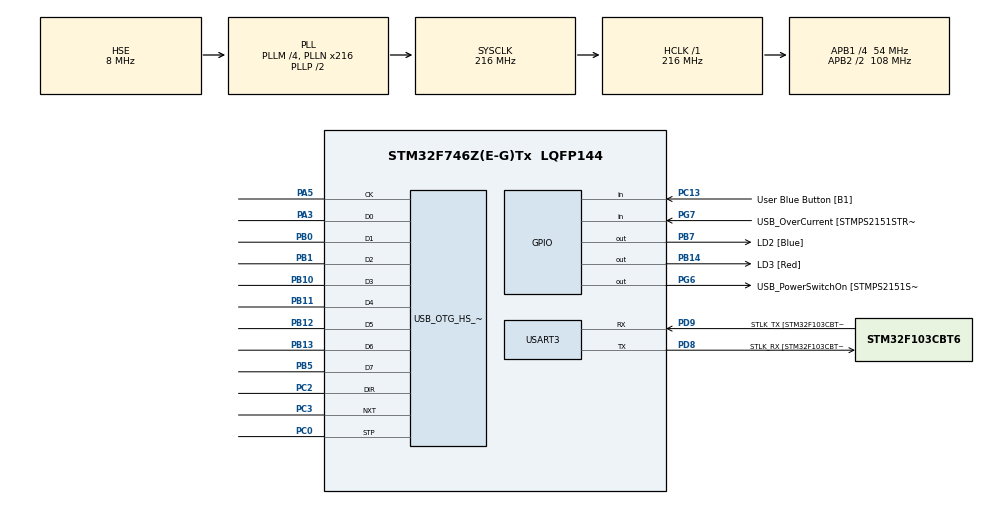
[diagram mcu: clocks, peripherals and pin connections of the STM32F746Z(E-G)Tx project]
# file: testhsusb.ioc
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Mcu.Family=STM32F7
Mcu.Name=STM32F746Z(E-G)Tx
Mcu.Package=LQFP144
NVIC.OTG_HS_IRQn=true\:0\:0\:false\:false\:true
NVIC.PriorityGroup=NVIC_PRIORITYGROUP_4
NVIC.TIM7_IRQn=true\:0\:0\:false\:false\:true
NVIC.TimeBase=TIM7_IRQn
NVIC.TimeBaseIP=TIM7
PA10.GPIO_Label=USB_ID
PA10.Signal=USB_OTG_FS_ID
PA11.GPIO_Label=USB_DM
PA11.Signal=USB_OTG_FS_DM
PA12.GPIO_Label=USB_DP
PA12.Signal=USB_OTG_FS_DP
PA13.GPIO_Label=TMS
PA13.Mode=Serial_Wire
PA13.Signal=SYS_JTMS-SWDIO
PA14.GPIO_Label=TCK
PA14.Mode=Serial_Wire
PA14.Signal=SYS_JTCK-SWCLK
PA3.Mode=Device_HS
PA3.Signal=USB_OTG_HS_ULPI_D0
PA5.Mode=Device_HS
PA5.Signal=USB_OTG_HS_ULPI_CK
PA8.GPIO_Label=USB_SOF [TP1]
PA8.Signal=USB_OTG_FS_SOF
PA9.GPIO_Label=USB_VBUS
PA9.Signal=USB_OTG_FS_VBUS
PB0.Mode=Device_HS
PB0.Signal=USB_OTG_HS_ULPI_D1
PB1.Mode=Device_HS
PB1.Signal=USB_OTG_HS_ULPI_D2
PB10.Mode=Device_HS
PB10.Signal=USB_OTG_HS_ULPI_D3
PB11.Mode=Device_HS
PB11.Signal=USB_OTG_HS_ULPI_D4
PB12.Mode=Device_HS
PB12.Signal=USB_OTG_HS_ULPI_D5
PB13.Mode=Device_HS
PB13.Signal=USB_OTG_HS_ULPI_D6
PB14.GPIO_Label=LD3 [Red]
PB14.Signal=GPIO_Output
PB5.Mode=Device_HS
PB5.Signal=USB_OTG_HS_ULPI_D7
PB7.GPIO_Label=LD2 [Blue]
PB7.Signal=GPIO_Output
PC0.Mode=Device_HS
PC0.Signal=USB_OTG_HS_ULPI_STP
PC13.GPIO_Label=User Blue Button [B1]
PC13.Signal=GPIO_Input
PC14/OSC32_IN.Mode=LSE-External-Oscillator
PC14/OSC32_IN.Signal=RCC_OSC32_IN
PC15/OSC32_OUT.Mode=LSE-External-Oscillator
PC15/OSC32_OUT.Signal=RCC_OSC32_OUT
PC2.Mode=Device_HS
PC2.Signal=USB_OTG_HS_ULPI_DIR
PC3.Mode=Device_HS
PC3.Signal=USB_OTG_HS_ULPI_NXT
PD8.GPIO_Label=STLK_RX [STM32F103CBT6_PA3]
PD8.Mode=Asynchronous
PD8.Signal=USART3_TX
PD9.GPIO_Label=STLK_TX [STM32F103CBT6_PA2]
PD9.Mode=Asynchronous
PD9.Signal=USART3_RX
PG6.GPIO_Label=USB_PowerSwitchOn [STMPS2151STR_EN]
PG6.Signal=GPIO_Output
PG7.GPIO_Label=USB_OverCurrent [STMPS2151STR_FAULT]
PG7.Signal=GPIO_Input
PH0/OSC_IN.GPIO_Label=MCO [STM32F103CBT6_PA8]
PH0/OSC_IN.Mode=HSE-External-Clock-Source
PH0/OSC_IN.Signal=RCC_OSC_IN
PH1/OSC_OUT.Mode=HSE-External-Clock-Source
PH1/OSC_OUT.Signal=RCC_OSC_OUT
ProjectManager.HeapSize=0x4800
ProjectManager.StackSize=0x2400
ProjectManager.TargetToolchain=MDK-ARM V5
RCC.48MHZClocksFreq_Value=24000000
RCC.AHBFreq_Value=216000000
RCC.APB1CLKDivider=RCC_HCLK_DIV4
RCC.APB1Freq_Value=54000000
RCC.APB1TimFreq_Value=108000000
RCC.APB2CLKDivider=RCC_HCLK_DIV2
RCC.APB2Freq_Value=108000000
RCC.APB2TimFreq_Value=216000000
RCC.CortexFreq_Value=216000000
RCC.HCLKFreq_Value=216000000
RCC.HSE_VALUE=8000000
RCC.HSI_VALUE=16000000
RCC.PLLM=4
RCC.PLLMUL=RCC_PLL_MUL9
RCC.PLLN=216
RCC.PLLSourceVirtual=RCC_PLLSOURCE_HSE
RCC.PRESCALERUSB=RCC_USBCLKSOURCE_PLL_DIV1_5
RCC.SYSCLKFreq_VALUE=216000000
RCC.SYSCLKSource=RCC_SYSCLKSOURCE_PLLCLK
RCC.SYSCLKSourceVirtual=RCC_SYSCLKSOURCE_PLLCLK
RCC.USBFreq_Value=216000000
RCC.VCOOutputFreq_Value=432000000
USART3.WordLength=UART_WORDLENGTH_8B
USB_DEVICE.CLASS_NAME-HID_HS=HID
USB_DEVICE.USBD_HandleTypeDef-HID_HS=hUsbDeviceHS
USB_DEVICE.VirtualMode-HID_HS=Hid
USB_DEVICE.VirtualModeHS=Hid_HS
USB_OTG_HS.VirtualMode-Device_HS=Device_HS
VP_SYS_VS_tim7.Mode=TIM7
VP_USB_DEVICE_VS_USB_DEVICE_HID_HS.Mode=HID_HS
board=NUCLEO-F746ZG

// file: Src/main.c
/**
  ******************************************************************************
  * File Name          : main.c
  * Description        : Main program body
  ******************************************************************************
  *
  * COPYRIGHT(c) 2016 STMicroelectronics
  *
  * Redistribution and use in source and binary forms, with or without modification,
  * are permitted provided that the following conditions are met:
  *   1. Redistributions of source code must retain the above copyright notice,
  *      this list of conditions and the following disclaimer.
  *   2. Redistributions in binary form must reproduce the above copyright notice,
  *      this list of conditions and the following disclaimer in the documentation
  *      and/or other materials provided with the distribution.
  *   3. Neither the name of STMicroelectronics nor the names of its contributors
  *      may be used to endorse or promote products derived from this software
  *      without specific prior written permission.
  *
  * THIS SOFTWARE IS PROVIDED BY THE COPYRIGHT HOLDERS AND CONTRIBUTORS "AS IS"
  * AND ANY EXPRESS OR IMPLIED WARRANTIES, INCLUDING, BUT NOT LIMITED TO, THE
  * IMPLIED WARRANTIES OF MERCHANTABILITY AND FITNESS FOR A PARTICULAR PURPOSE ARE
  * DISCLAIMED. IN NO EVENT SHALL THE COPYRIGHT HOLDER OR CONTRIBUTORS BE LIABLE
  * FOR ANY DIRECT, INDIRECT, INCIDENTAL, SPECIAL, EXEMPLARY, OR CONSEQUENTIAL
  * DAMAGES (INCLUDING, BUT NOT LIMITED TO, PROCUREMENT OF SUBSTITUTE GOODS OR
  * SERVICES; LOSS OF USE, DATA, OR PROFITS; OR BUSINESS INTERRUPTION) HOWEVER
  * CAUSED AND ON ANY THEORY OF LIABILITY, WHETHER IN CONTRACT, STRICT LIABILITY,
  * OR TORT (INCLUDING NEGLIGENCE OR OTHERWISE) ARISING IN ANY WAY OUT OF THE USE
  * OF THIS SOFTWARE, EVEN IF ADVISED OF THE POSSIBILITY OF SUCH DAMAGE.
  *
  ******************************************************************************
  */
#include "stm32f7xx_hal.h"
#include "usb_device.h"

UART_HandleTypeDef huart3;

/* USER CODE BEGIN PV */
/* Private variables ---------------------------------------------------------*/

/* USER CODE END PV */

void SystemClock_Config(void);
void Error_Handler(void);
static void MX_GPIO_Init(void);
static void MX_USART3_UART_Init(void);

/* USER CODE BEGIN PFP */
/* Private function prototypes -----------------------------------------------*/

/* USER CODE END PFP */

int main(void)
{

  /* MCU Configuration----------------------------------------------------------*/

  /* Reset of all peripherals, Initializes the Flash interface and the Systick. */
  HAL_Init();

  /* Configure the system clock */
  SystemClock_Config();

  /* Initialize all configured peripherals */
  MX_GPIO_Init();
  MX_USART3_UART_Init();
  MX_USB_DEVICE_Init();

  /* Infinite loop */
  while (1)
  {

  }

}

/** System Clock Configuration
*/
void SystemClock_Config(void)
{

  RCC_OscInitTypeDef RCC_OscInitStruct;
  RCC_ClkInitTypeDef RCC_ClkInitStruct;
  RCC_PeriphCLKInitTypeDef PeriphClkInitStruct;

  __HAL_RCC_PWR_CLK_ENABLE();

  __HAL_PWR_VOLTAGESCALING_CONFIG(PWR_REGULATOR_VOLTAGE_SCALE1);

  RCC_OscInitStruct.OscillatorType = RCC_OSCILLATORTYPE_HSE;
  RCC_OscInitStruct.HSEState = RCC_HSE_BYPASS;
  RCC_OscInitStruct.PLL.PLLState = RCC_PLL_ON;
  RCC_OscInitStruct.PLL.PLLSource = RCC_PLLSOURCE_HSE;
  RCC_OscInitStruct.PLL.PLLM = 4;
  RCC_OscInitStruct.PLL.PLLN = 216;
  RCC_OscInitStruct.PLL.PLLP = RCC_PLLP_DIV2;
  RCC_OscInitStruct.PLL.PLLQ = 2;
  if (HAL_RCC_OscConfig(&RCC_OscInitStruct) != HAL_OK)
  {
    Error_Handler();
  }

  if (HAL_PWREx_EnableOverDrive() != HAL_OK)
  {
    Error_Handler();
  }

  RCC_ClkInitStruct.ClockType = RCC_CLOCKTYPE_HCLK|RCC_CLOCKTYPE_SYSCLK
                              |RCC_CLOCKTYPE_PCLK1|RCC_CLOCKTYPE_PCLK2;
  RCC_ClkInitStruct.SYSCLKSource = RCC_SYSCLKSOURCE_PLLCLK;
  RCC_ClkInitStruct.AHBCLKDivider = RCC_SYSCLK_DIV1;
  RCC_ClkInitStruct.APB1CLKDivider = RCC_HCLK_DIV4;
  RCC_ClkInitStruct.APB2CLKDivider = RCC_HCLK_DIV2;
  if (HAL_RCC_ClockConfig(&RCC_ClkInitStruct, FLASH_LATENCY_7) != HAL_OK)
  {
    Error_Handler();
  }

  PeriphClkInitStruct.PeriphClockSelection = RCC_PERIPHCLK_USART3;
  PeriphClkInitStruct.Usart3ClockSelection = RCC_USART3CLKSOURCE_PCLK1;
  if (HAL_RCCEx_PeriphCLKConfig(&PeriphClkInitStruct) != HAL_OK)
  {
    Error_Handler();
  }

  HAL_SYSTICK_Config(HAL_RCC_GetHCLKFreq()/1000);

  HAL_SYSTICK_CLKSourceConfig(SYSTICK_CLKSOURCE_HCLK);

  /* SysTick_IRQn interrupt configuration */
  HAL_NVIC_SetPriority(SysTick_IRQn, 0, 0);
}

/* USART3 init function */
static void MX_USART3_UART_Init(void)
{

  huart3.Instance = USART3;
  huart3.Init.BaudRate = 115200;
  huart3.Init.WordLength = UART_WORDLENGTH_8B;
  huart3.Init.StopBits = UART_STOPBITS_1;
  huart3.Init.Parity = UART_PARITY_NONE;
  huart3.Init.Mode = UART_MODE_TX_RX;
  huart3.Init.HwFlowCtl = UART_HWCONTROL_NONE;
  huart3.Init.OverSampling = UART_OVERSAMPLING_16;
  huart3.Init.OneBitSampling = UART_ONE_BIT_SAMPLE_DISABLE;
  huart3.AdvancedInit.AdvFeatureInit = UART_ADVFEATURE_NO_INIT;
  if (HAL_UART_Init(&huart3) != HAL_OK)
  {
    Error_Handler();
  }

}

/** Configure pins as
        * Analog
        * Input
        * Output
        * EVENT_OUT
        * EXTI
     PA8   ------> USB_OTG_FS_SOF
     PA10   ------> USB_OTG_FS_ID
     PA11   ------> USB_OTG_FS_DM
     PA12   ------> USB_OTG_FS_DP
*/
static void MX_GPIO_Init(void)
{

  GPIO_InitTypeDef GPIO_InitStruct;

  /* GPIO Ports Clock Enable */
  __HAL_RCC_GPIOC_CLK_ENABLE();
  __HAL_RCC_GPIOH_CLK_ENABLE();
  __HAL_RCC_GPIOA_CLK_ENABLE();
  __HAL_RCC_GPIOB_CLK_ENABLE();
  __HAL_RCC_GPIOD_CLK_ENABLE();
  __HAL_RCC_GPIOG_CLK_ENABLE();

  /*Configure GPIO pin : User_Blue_Button_Pin */
  GPIO_InitStruct.Pin = User_Blue_Button_Pin;
  GPIO_InitStruct.Mode = GPIO_MODE_INPUT;
  GPIO_InitStruct.Pull = GPIO_NOPULL;
  HAL_GPIO_Init(User_Blue_Button_GPIO_Port, &GPIO_InitStruct);

  /*Configure GPIO pins : LD3_Pin LD2_Pin */
  GPIO_InitStruct.Pin = LD3_Pin|LD2_Pin;
  GPIO_InitStruct.Mode = GPIO_MODE_OUTPUT_PP;
  GPIO_InitStruct.Pull = GPIO_NOPULL;
  GPIO_InitStruct.Speed = GPIO_SPEED_FREQ_LOW;
  HAL_GPIO_Init(GPIOB, &GPIO_InitStruct);

  /*Configure GPIO pin : USB_PowerSwitchOn_Pin */
  GPIO_InitStruct.Pin = USB_PowerSwitchOn_Pin;
  GPIO_InitStruct.Mode = GPIO_MODE_OUTPUT_PP;
  GPIO_InitStruct.Pull = GPIO_NOPULL;
  GPIO_InitStruct.Speed = GPIO_SPEED_FREQ_LOW;
  HAL_GPIO_Init(USB_PowerSwitchOn_GPIO_Port, &GPIO_InitStruct);

  /*Configure GPIO pin : USB_OverCurrent_Pin */
  GPIO_InitStruct.Pin = USB_OverCurrent_Pin;
  GPIO_InitStruct.Mode = GPIO_MODE_INPUT;
  GPIO_InitStruct.Pull = GPIO_NOPULL;
  HAL_GPIO_Init(USB_OverCurrent_GPIO_Port, &GPIO_InitStruct);

  /*Configure GPIO pins : USB_SOF_Pin USB_ID_Pin USB_DM_Pin USB_DP_Pin */
  GPIO_InitStruct.Pin = USB_SOF_Pin|USB_ID_Pin|USB_DM_Pin|USB_DP_Pin;
  GPIO_InitStruct.Mode = GPIO_MODE_AF_PP;
  GPIO_InitStruct.Pull = GPIO_NOPULL;
  GPIO_InitStruct.Speed = GPIO_SPEED_FREQ_VERY_HIGH;
  GPIO_InitStruct.Alternate = GPIO_AF10_OTG_FS;
  HAL_GPIO_Init(GPIOA, &GPIO_InitStruct);

  /*Configure GPIO pin Output Level */
  HAL_GPIO_WritePin(GPIOB, LD3_Pin|LD2_Pin, GPIO_PIN_RESET);

  /*Configure GPIO pin Output Level */
  HAL_GPIO_WritePin(USB_PowerSwitchOn_GPIO_Port, USB_PowerSwitchOn_Pin, GPIO_PIN_RESET);

}

void HAL_TIM_PeriodElapsedCallback(TIM_HandleTypeDef *htim)
{
  if (htim->Instance == TIM7) {
    HAL_IncTick();
  }
}

void Error_Handler(void)
{
  /* USER CODE BEGIN Error_Handler */
  /* User can add his own implementation to report the HAL error return state */
  while(1)
  {
		HAL_GPIO_TogglePin(LD2_GPIO_Port, LD2_Pin);
		HAL_Delay(250);
  }
  /* USER CODE END Error_Handler */
}

/************************ (C) COPYRIGHT STMicroelectronics *****END OF FILE****/
